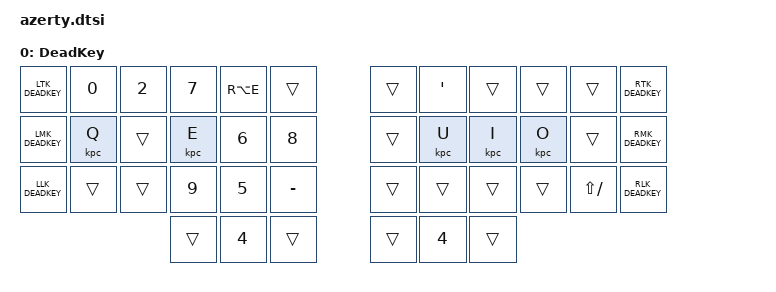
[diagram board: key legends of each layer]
#define DK_LAYER EXTRA_LAYERS_START_INDEX


&base_layer {
  display-name = "Base";
  bindings = <
   LTK_AZERTY  &kp Q  &kp W  &kp E  &kp R  &kp T        &kp Y  &kp U  &kp I     &kp O   &kp P     RTK_AZERTY
   LMK_AZERTY  HRM_A  HRM_S  HRM_D  HRM_F  &kp G        &kp H  HRM_J  HRM_K     HRM_L   HRM_SEMI  RMK_AZERTY
   LLK_AZERTY  &kp Z  &kp X  &kp C  &kp V  &kp B        &kp N  &kp M  &kp COMMA &kp DOT &kp FSLH  LLK_AZERTY
            LTHUMB_TUCK  LTHUMB_HOME  LTHUMB_REACH    RTHUMB_REACH  RTHUMB_HOME  RTHUMB_TUCK
  >;
};

/ {
  macros {
    kpc: circumflex {
      compatible = "zmk,behavior-macro-one-param";
      #binding-cells = <1>;
      tap-ms = <0>;
      wait-ms = <0>;
      bindings
        = <&macro_tap &kp LBKT>
        , <&macro_pause_for_release>
        , <&macro_param_1to1>
        , <&kp MACRO_PLACEHOLDER>
        ;
    };
    spc: space_after_dk {
      compatible = "zmk,behavior-macro-one-param";
      #binding-cells = <1>;
      tap-ms = <0>;
      wait-ms = <0>;
      bindings
        = <&macro_param_1to1>
        , <&kp MACRO_PLACEHOLDER>
        , <&macro_pause_for_release>
        , <&macro_tap &kp SPACE>
        ;
    };
  };

  // Extra layers defined specifically for this keymap, appended to the base keymap.
  keymap {
    compatible = "zmk,keymap";

    dead_key_layer {
      display-name = "DeadKey";
      bindings = <
        LTK_DEADKEY  &kp N0  &kp N2  &kp N7  &kp RA(E) &trans     &trans  &kp SQT &trans  &trans  &trans       RTK_DEADKEY
        LMK_DEADKEY  &kpc Q  &trans  &kpc E  &kp N6  &kp N8       &trans  &kpc U  &kpc I  &kpc O  &trans       RMK_DEADKEY
        LLK_DEADKEY  &trans  &trans  &kp N9  &kp N5  &kp MINUS    &trans  &trans  &trans  &trans  &kp LS(FSLH) RLK_DEADKEY
                                  &trans  &kp N4  &trans       &trans  &kp N4  &trans
      >;
    };
  };
};
